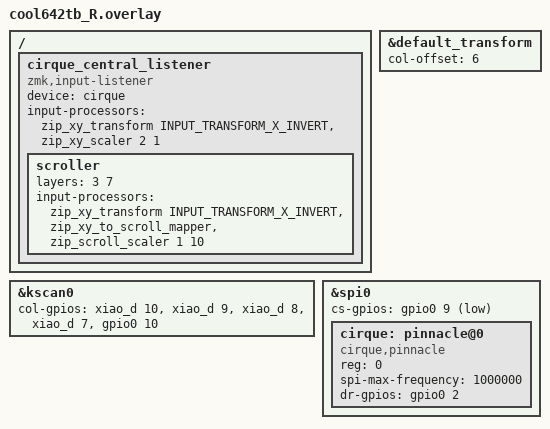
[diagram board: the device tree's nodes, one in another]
#include "cool642tb.dtsi"
#include <input/processors.dtsi>
#include <zephyr/dt-bindings/input/input-event-codes.h>
#include <zephyr/dt-bindings/pinctrl/nrf-pinctrl.h>

&default_transform {
    col-offset = <6>;
};

&kscan0 {
    col-gpios =
        <&xiao_d 10 (GPIO_ACTIVE_HIGH)>,
        <&xiao_d 9  (GPIO_ACTIVE_HIGH)>,
        <&xiao_d 8  (GPIO_ACTIVE_HIGH)>,
        <&xiao_d 7  (GPIO_ACTIVE_HIGH)>,
        <&gpio0 10  (GPIO_ACTIVE_HIGH)>;
};



&spi0 {
    status = "okay";
    cs-gpios = <&gpio0 9 (GPIO_ACTIVE_LOW)>;

    cirque: pinnacle@0 {
        status = "okay";
        compatible = "cirque,pinnacle";
        reg = <0>;
        spi-max-frequency = <1000000>;
        dr-gpios = <&gpio0 2 (GPIO_PULL_UP | GPIO_ACTIVE_HIGH)>;
    };
};

/ {
    cirque_central_listener: cirque_central_listener {
        compatible = "zmk,input-listener";
        status = "okay";
        device = <&cirque>;

        input-processors = <
            &zip_xy_transform INPUT_TRANSFORM_X_INVERT
            &zip_xy_scaler 2 1
        >;

        scroller {
            layers = <3 7>;
            input-processors = <
                &zip_xy_transform INPUT_TRANSFORM_X_INVERT
                &zip_xy_to_scroll_mapper
                &zip_scroll_scaler 1 10
            >;
        };
    };
};
